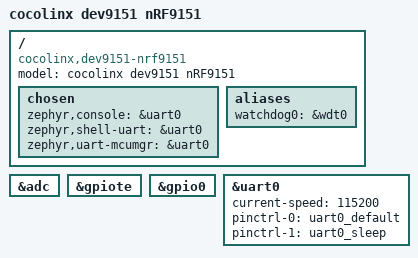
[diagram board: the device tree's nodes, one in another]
/*
 * Copyright (c) 2023 cocolinx
 *
 * SPDX-License-Identifier: Apache-2.0
 */
#include "cocolinx_dev9151_nrf9151_common-pinctrl.dtsi"
#include <zephyr/dt-bindings/input/input-event-codes.h>

/ {
	model = "cocolinx dev9151 nRF9151";
	compatible = "cocolinx,dev9151-nrf9151";

	chosen {
		zephyr,console = &uart0;
		zephyr,shell-uart = &uart0;
		zephyr,uart-mcumgr = &uart0;
	};

	aliases {
		watchdog0 = &wdt0;
	};
};

&adc {
	status = "okay";
};

&gpiote {
	status = "okay";
};

&gpio0 {
	status = "okay";
};

&uart0 {
	status = "okay";
	current-speed = <115200>;
	pinctrl-0 = <&uart0_default>;
	pinctrl-1 = <&uart0_sleep>;
	pinctrl-names = "default", "sleep";
};

// &uart2 {
// 	status = "okay";
// 	current-speed = <115200>;
// 	pinctrl-0 = <&uart2_default>;
// 	pinctrl-1 = <&uart2_sleep>;
// 	pinctrl-names = "default", "sleep";
// };

// &spi3 {
// 	compatible = "nordic,nrf-spim";
// 	status = "okay";
// 	cs-gpios = < &gpio0 30 GPIO_ACTIVE_LOW >;
// 	pinctrl-0 = <&spi3_default>;
// 	pinctrl-1 = <&spi3_sleep>;
// 	pinctrl-names = "default", "sleep";	
// };

// &i2c1 {
// 	compatible = "nordic,nrf-twim";
// 	status = "okay";
// 	pinctrl-0 = <&i2c1_default>;
// 	pinctrl-1 = <&i2c1_sleep>;
// 	pinctrl-names = "default", "sleep";
// };

// &pwm0 {
// 	status = "okay";
// 	pinctrl-0 = <&pwm0_default>;
// 	pinctrl-1 = <&pwm0_sleep>;
// 	pinctrl-names = "default", "sleep";
// };

/* Include default memory partition configuration file */
#include <nordic/nrf91xx_partition.dtsi>
